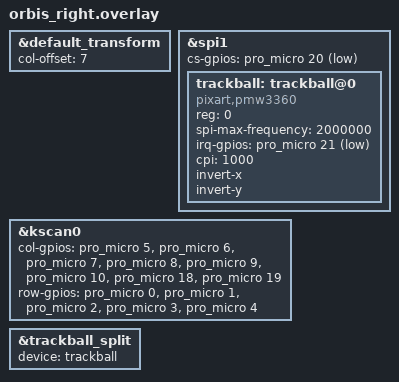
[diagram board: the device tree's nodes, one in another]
/*
 * Orbis 右手（外围 / peripheral）overlay
 *   - 5 行 × 8 列矩阵，40 键（正好填满 40 格）
 *   - PMW3360 轨迹球走 SPI，MOTION 接中断脚
 *   - 轨迹球装在外壳上，经 J2 排线接入
 *
 * SPDX-License-Identifier: MIT
 */

#include "orbis.dtsi"

/* 右手矩阵从虚拟列 7 开始 */
&default_transform {
    col-offset = <7>;
};

&spi1 {
    status = "okay";
    cs-gpios = <&pro_micro 20 GPIO_ACTIVE_LOW>;   /* 3360 NCS  D20  P0.29 */

    trackball: trackball@0 {
        compatible = "pixart,pmw3360";
        status = "okay";
        reg = <0>;
        spi-max-frequency = <2000000>;

        /* MOTION 中断脚：接上以后驱动只在球动时唤醒 MCU，可以开深睡 */
        irq-gpios = <&pro_micro 21 (GPIO_ACTIVE_LOW | GPIO_PULL_UP)>;   /* D21  P0.31 */

        cpi = <1000>;
        /* 装反了就改用 rotate-90 / rotate-180 / rotate-270，或去掉 invert-* */
        invert-x;
        invert-y;
    };
};

&kscan0 {
    col-gpios
        = <&pro_micro 5 GPIO_ACTIVE_HIGH>    /* COL0  D5  P0.24 */
        , <&pro_micro 6 GPIO_ACTIVE_HIGH>    /* COL1  D6  P1.00 */
        , <&pro_micro 7 GPIO_ACTIVE_HIGH>    /* COL2  D7  P0.11 */
        , <&pro_micro 8 GPIO_ACTIVE_HIGH>    /* COL3  D8  P1.04 */
        , <&pro_micro 9 GPIO_ACTIVE_HIGH>    /* COL4  D9  P1.06 */
        , <&pro_micro 10 GPIO_ACTIVE_HIGH>    /* COL5  D10  P0.09 */
        , <&pro_micro 18 GPIO_ACTIVE_HIGH>    /* COL6  D18  P1.15 */
        , <&pro_micro 19 GPIO_ACTIVE_HIGH>    /* COL7  D19  P0.02 */
        ;
    row-gpios
        = <&pro_micro 0 (GPIO_ACTIVE_HIGH | GPIO_PULL_DOWN)>   /* ROW0  D0  P0.08 */
        , <&pro_micro 1 (GPIO_ACTIVE_HIGH | GPIO_PULL_DOWN)>   /* ROW1  D1  P0.06 */
        , <&pro_micro 2 (GPIO_ACTIVE_HIGH | GPIO_PULL_DOWN)>   /* ROW2  D2  P0.17 */
        , <&pro_micro 3 (GPIO_ACTIVE_HIGH | GPIO_PULL_DOWN)>   /* ROW3  D3  P0.20 */
        , <&pro_micro 4 (GPIO_ACTIVE_HIGH | GPIO_PULL_DOWN)>   /* ROW4  D4  P0.22 */
        ;
};

&trackball_split {
    device = <&trackball>;
};
